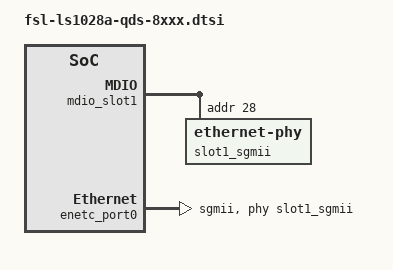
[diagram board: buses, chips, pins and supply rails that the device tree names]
// SPDX-License-Identifier: (GPL-2.0+ OR MIT)
/*
 * Device Tree Include file for LS1028A QDS board, serdes 8xxx
 *
 * Copyright 2019 NXP
 *
 */

&mdio_slot1 {
	slot1_sgmii: ethernet-phy@1c {
		/* 1st port on VSC8234 */
		reg = <0x1c>;
	};
};

&enetc_port0 {
	phy-handle = <&slot1_sgmii>;
	phy-connection-type = "sgmii";
};
